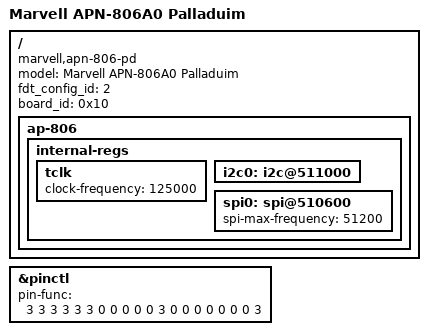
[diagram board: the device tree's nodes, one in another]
/*
 * ***************************************************************************
 * Copyright (C) 2015 Marvell International Ltd.
 * ***************************************************************************
 * This program is free software: you can redistribute it and/or modify it
 * under the terms of the GNU General Public License as published by the Free
 * Software Foundation, either version 2 of the License, or any later version.
 *
 * This program is distributed in the hope that it will be useful,
 * but WITHOUT ANY WARRANTY; without even the implied warranty of
 * MERCHANTABILITY or FITNESS FOR A PARTICULAR PURPOSE.  See the
 * GNU General Public License for more details.
 *
 * You should have received a copy of the GNU General Public License
 * along with this program.  If not, see <http://www.gnu.org/licenses/>.
 * ***************************************************************************
 */

/dts-v1/;

#include <dt-bindings/gpio/armada-8k-gpio.h>
#include "apn-806-a0.dtsi"

/ {
	model = "Marvell APN-806A0 Palladuim";
	compatible = "marvell,apn-806-pd", "marvell,apn-806";
	fdt_config_id = <2>;
	board_id = <0x10>;

	ap-806 {
		internal-regs {
			tclk: tclk {
				clock-frequency = <125000>;
			};

			i2c0: i2c@511000 {
				status = "okay";
			};

			spi0: spi@510600 {
				spi-max-frequency = <51200>;
				status = "okay";
			};
		};
	};
};

&pinctl {
		  /* 0 1 2 3 4 5 6 7 8 9 */
	pin-func = < 3 3 3 3 3 3 0 0 0 0
		     0 3 0 0 0 0 0 0 0 3 >;
};
